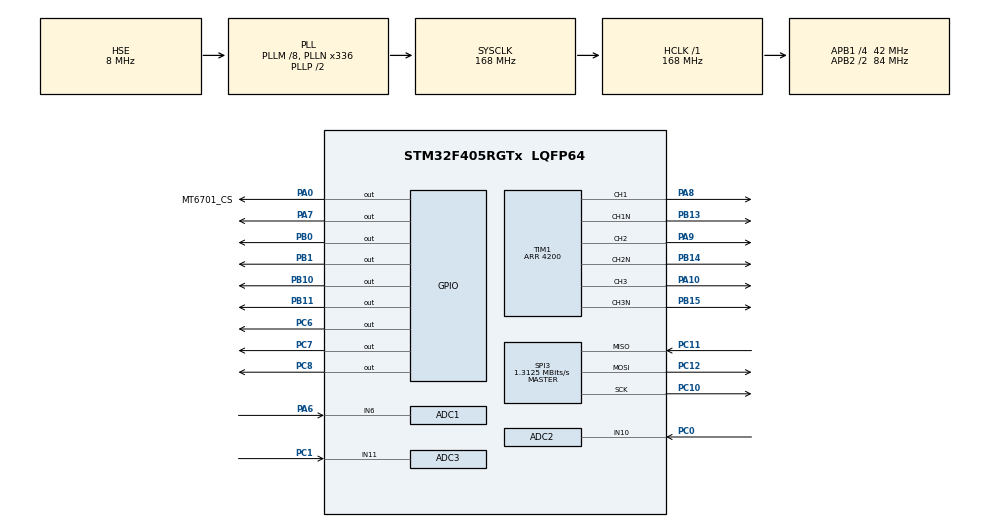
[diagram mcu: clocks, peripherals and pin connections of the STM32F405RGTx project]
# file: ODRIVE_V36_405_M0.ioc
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ADC1.Channel-0\#ChannelRegularConversion=ADC_CHANNEL_6
ADC1.Channel-1\#ChannelRegularConversion=ADC_CHANNEL_VREFINT
ADC1.ClockPrescaler=ADC_CLOCK_SYNC_PCLK_DIV4
ADC1.EOCSelection=ADC_EOC_SEQ_CONV
ADC1.NbrOfConversion=2
ADC1.NbrOfConversionFlag=1
ADC1.Rank-0\#ChannelRegularConversion=1
ADC1.Rank-1\#ChannelRegularConversion=2
ADC1.SamplingTime-0\#ChannelRegularConversion=ADC_SAMPLETIME_480CYCLES
ADC1.SamplingTime-1\#ChannelRegularConversion=ADC_SAMPLETIME_480CYCLES
ADC1.ScanConvMode=ENABLE
ADC1.master=1
ADC2.Channel-0\#ChannelInjectedConversion=ADC_CHANNEL_10
ADC2.Channel-0\#ChannelRegularConversion=ADC_CHANNEL_10
ADC2.ClockPrescaler=ADC_CLOCK_SYNC_PCLK_DIV4
ADC2.ExternalTrigInjecConv=ADC_EXTERNALTRIGINJECCONV_T1_TRGO
ADC2.ExternalTrigInjecConvEdge=ADC_EXTERNALTRIGINJECCONVEDGE_RISING
ADC2.InjNumberOfConversion=1
ADC2.InjectedConvMode=None
ADC2.InjectedRank-0\#ChannelInjectedConversion=1
ADC2.NbrOfConversionFlag=1
ADC2.Rank-0\#ChannelRegularConversion=1
ADC2.SamplingTime-0\#ChannelInjectedConversion=ADC_SAMPLETIME_15CYCLES
ADC2.SamplingTime-0\#ChannelRegularConversion=ADC_SAMPLETIME_3CYCLES
ADC3.Channel-0\#ChannelInjectedConversion=ADC_CHANNEL_11
ADC3.Channel-0\#ChannelRegularConversion=ADC_CHANNEL_11
ADC3.ClockPrescaler=ADC_CLOCK_SYNC_PCLK_DIV4
ADC3.ExternalTrigInjecConv=ADC_EXTERNALTRIGINJECCONV_T1_TRGO
ADC3.ExternalTrigInjecConvEdge=ADC_EXTERNALTRIGINJECCONVEDGE_RISING
ADC3.InjNumberOfConversion=1
ADC3.InjectedConvMode=None
ADC3.InjectedRank-0\#ChannelInjectedConversion=1
ADC3.NbrOfConversionFlag=1
ADC3.Rank-0\#ChannelRegularConversion=1
ADC3.SamplingTime-0\#ChannelInjectedConversion=ADC_SAMPLETIME_15CYCLES
ADC3.SamplingTime-0\#ChannelRegularConversion=ADC_SAMPLETIME_3CYCLES
Dma.ADC1.0.Direction=DMA_PERIPH_TO_MEMORY
Dma.ADC1.0.FIFOMode=DMA_FIFOMODE_DISABLE
Dma.ADC1.0.Instance=DMA2_Stream0
Dma.ADC1.0.MemDataAlignment=DMA_MDATAALIGN_HALFWORD
Dma.ADC1.0.MemInc=DMA_MINC_ENABLE
Dma.ADC1.0.Mode=DMA_NORMAL
Dma.ADC1.0.PeriphDataAlignment=DMA_PDATAALIGN_HALFWORD
Dma.ADC1.0.PeriphInc=DMA_PINC_DISABLE
Dma.ADC1.0.Priority=DMA_PRIORITY_HIGH
Dma.Request0=ADC1
Mcu.Family=STM32F4
Mcu.Name=STM32F405RGTx
Mcu.Package=LQFP64
NVIC.ADC_IRQn=true\:2\:0\:false\:false\:true\:true\:true\:true
NVIC.DMA2_Stream0_IRQn=true\:4\:0\:false\:false\:true\:true\:true\:true
NVIC.PriorityGroup=NVIC_PRIORITYGROUP_4
NVIC.SPI3_IRQn=true\:3\:0\:false\:false\:true\:true\:true\:true
NVIC.TIM1_UP_TIM10_IRQn=true\:1\:0\:false\:false\:true\:true\:true\:true
NVIC.TIM2_IRQn=true\:5\:0\:false\:false\:true\:true\:true\:true
PA0-WKUP.GPIO_Label=MT6701_CS
PA0-WKUP.PinState=GPIO_PIN_SET
PA0-WKUP.Signal=GPIO_Output
PA10.GPIO_PuPd=GPIO_PULLDOWN
PA10.Signal=S_TIM1_CH3
PA13.Mode=Serial_Wire
PA13.Signal=SYS_JTMS-SWDIO
PA14.Mode=Serial_Wire
PA14.Signal=SYS_JTCK-SWCLK
PA6.Signal=ADCx_IN6
PA7.Signal=GPIO_Output
PA8.GPIO_PuPd=GPIO_PULLDOWN
PA8.Signal=S_TIM1_CH1
PA9.GPIO_PuPd=GPIO_PULLDOWN
PA9.Signal=S_TIM1_CH2
PB0.Signal=GPIO_Output
PB1.Signal=GPIO_Output
PB10.Signal=GPIO_Output
PB11.Signal=GPIO_Output
PB13.GPIO_PuPd=GPIO_PULLDOWN
PB13.Mode=PWM Generation1 CH1 CH1N
PB13.Signal=TIM1_CH1N
PB14.GPIO_PuPd=GPIO_PULLDOWN
PB14.Mode=PWM Generation2 CH2 CH2N
PB14.Signal=TIM1_CH2N
PB15.GPIO_PuPd=GPIO_PULLDOWN
PB15.Mode=PWM Generation3 CH3 CH3N
PB15.Signal=TIM1_CH3N
PC0.Signal=ADCx_IN10
PC1.Signal=ADCx_IN11
PC10.Mode=Full_Duplex_Master
PC10.Signal=SPI3_SCK
PC11.Mode=Full_Duplex_Master
PC11.Signal=SPI3_MISO
PC12.Mode=Full_Duplex_Master
PC12.Signal=SPI3_MOSI
PC6.Signal=GPIO_Output
PC7.Signal=GPIO_Output
PC8.Signal=GPIO_Output
PH0-OSC_IN.Mode=HSE-External-Oscillator
PH0-OSC_IN.Signal=RCC_OSC_IN
PH1-OSC_OUT.Mode=HSE-External-Oscillator
PH1-OSC_OUT.Signal=RCC_OSC_OUT
ProjectManager.HeapSize=0x200
ProjectManager.StackSize=0x1000
ProjectManager.TargetToolchain=MDK-ARM V5
RCC.48MHZClocksFreq_Value=48000000
RCC.AHBFreq_Value=168000000
RCC.APB1CLKDivider=RCC_HCLK_DIV4
RCC.APB1Freq_Value=42000000
RCC.APB1TimFreq_Value=84000000
RCC.APB2CLKDivider=RCC_HCLK_DIV2
RCC.APB2Freq_Value=84000000
RCC.APB2TimFreq_Value=168000000
RCC.CortexFreq_Value=168000000
RCC.HCLKFreq_Value=168000000
RCC.HSE_VALUE=8000000
RCC.HSI_VALUE=16000000
RCC.LSE_VALUE=32768
RCC.PLLM=8
RCC.PLLN=336
RCC.PLLQ=7
RCC.PLLSourceVirtual=RCC_PLLSOURCE_HSE
RCC.RCC_RTC_Clock_Source_FROM_HSE=RCC_RTCCLKSOURCE_HSE_DIV8
RCC.SYSCLKFreq_VALUE=168000000
RCC.SYSCLKSource=RCC_SYSCLKSOURCE_PLLCLK
RCC.VCOOutputFreq_Value=336000000
SH.ADCx_IN10.0=ADC2_IN10,IN10
SH.ADCx_IN11.0=ADC3_IN11,IN11
SH.ADCx_IN6.0=ADC1_IN6,IN6
SH.S_TIM1_CH1.0=TIM1_CH1,PWM Generation1 CH1 CH1N
SH.S_TIM1_CH2.0=TIM1_CH2,PWM Generation2 CH2 CH2N
SH.S_TIM1_CH3.0=TIM1_CH3,PWM Generation3 CH3 CH3N
SPI3.BaudRatePrescaler=SPI_BAUDRATEPRESCALER_32
SPI3.CLKPolarity=SPI_POLARITY_HIGH
SPI3.CalculateBaudRate=1.3125 MBits/s
SPI3.Direction=SPI_DIRECTION_2LINES
SPI3.Mode=SPI_MODE_MASTER
SPI3.VirtualType=VM_MASTER
TIM1.Channel-PWM\ Generation1\ CH1\ CH1N=TIM_CHANNEL_1
TIM1.Channel-PWM\ Generation2\ CH2\ CH2N=TIM_CHANNEL_2
TIM1.Channel-PWM\ Generation3\ CH3\ CH3N=TIM_CHANNEL_3
TIM1.Channel-PWM\ Generation4\ No\ Output=TIM_CHANNEL_4
TIM1.CounterMode=TIM_COUNTERMODE_CENTERALIGNED1
TIM1.DeadTime=84
TIM1.OCMode_PWM-PWM\ Generation4\ No\ Output=TIM_OCMODE_PWM2
TIM1.OffStateIDLEMode=TIM_OSSI_ENABLE
TIM1.OffStateRunMode=TIM_OSSR_ENABLE
TIM1.Period=4200
TIM1.Pulse-PWM\ Generation1\ CH1\ CH1N=2100
TIM1.Pulse-PWM\ Generation2\ CH2\ CH2N=2100
TIM1.Pulse-PWM\ Generation3\ CH3\ CH3N=2100
TIM1.Pulse-PWM\ Generation4\ No\ Output=4116
TIM1.TIM_MasterOutputTrigger=TIM_TRGO_OC4REF
TIM2.Period=4294967295
TIM2.Prescaler=83
VP_ADC1_Vref_Input.Mode=IN-Vrefint
VP_TIM1_VS_ClockSourceINT.Mode=Internal
VP_TIM1_VS_no_output4.Mode=PWM Generation4 No Output
VP_TIM2_VS_ClockSourceINT.Mode=Internal
board=custom

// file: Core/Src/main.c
/* USER CODE BEGIN Header */
/**
  ******************************************************************************
  * @file           : main.c
  * @brief          : Main program body
  ******************************************************************************
  * @attention
  *
  * Copyright (c) 2026 STMicroelectronics.
  * All rights reserved.
  *
  * This software is licensed under terms that can be found in the LICENSE file
  * in the root directory of this software component.
  * If no LICENSE file comes with this software, it is provided AS-IS.
  *
  ******************************************************************************
  */
/* USER CODE END Header */
#include "main.h"
#include "adc.h"
#include "dma.h"
#include "spi.h"
#include "tim.h"
#include "gpio.h"

/* USER CODE BEGIN Includes */
#include "target_validation.h"
/* USER CODE END Includes */

void SystemClock_Config(void);

int main(void)
{

  /* MCU Configuration--------------------------------------------------------*/

  /* Reset of all peripherals, Initializes the Flash interface and the Systick. */
  HAL_Init();

  /* Configure the system clock */
  SystemClock_Config();

  /* Initialize all configured peripherals */
  MX_GPIO_Init();
  MX_DMA_Init();
  MX_ADC1_Init();
  MX_ADC2_Init();
  MX_ADC3_Init();
  MX_SPI3_Init();
  MX_TIM1_Init();
  MX_TIM2_Init();
  /* USER CODE BEGIN 2 */
    if (!target_validation_start()) {
        Error_Handler();
    }
    /* 默认只有观测；台架动作通过独立 mailbox 显式提交。 */
/* USER CODE END 2 */

  /* Infinite loop */
  while (1)
  {

    /* USER CODE BEGIN 3 */
    __WFI();
  }
/* USER CODE END 3 */
}

void SystemClock_Config(void)
{
  RCC_OscInitTypeDef RCC_OscInitStruct = {0};
  RCC_ClkInitTypeDef RCC_ClkInitStruct = {0};

  /** Configure the main internal regulator output voltage
  */
  __HAL_RCC_PWR_CLK_ENABLE();
  __HAL_PWR_VOLTAGESCALING_CONFIG(PWR_REGULATOR_VOLTAGE_SCALE1);

  /** Initializes the RCC Oscillators according to the specified parameters
  * in the RCC_OscInitTypeDef structure.
  */
  RCC_OscInitStruct.OscillatorType = RCC_OSCILLATORTYPE_HSE;
  RCC_OscInitStruct.HSEState = RCC_HSE_ON;
  RCC_OscInitStruct.PLL.PLLState = RCC_PLL_ON;
  RCC_OscInitStruct.PLL.PLLSource = RCC_PLLSOURCE_HSE;
  RCC_OscInitStruct.PLL.PLLM = 8;
  RCC_OscInitStruct.PLL.PLLN = 336;
  RCC_OscInitStruct.PLL.PLLP = RCC_PLLP_DIV2;
  RCC_OscInitStruct.PLL.PLLQ = 7;
  if (HAL_RCC_OscConfig(&RCC_OscInitStruct) != HAL_OK)
  {
    Error_Handler();
  }

  /** Initializes the CPU, AHB and APB buses clocks
  */
  RCC_ClkInitStruct.ClockType = RCC_CLOCKTYPE_HCLK|RCC_CLOCKTYPE_SYSCLK
                              |RCC_CLOCKTYPE_PCLK1|RCC_CLOCKTYPE_PCLK2;
  RCC_ClkInitStruct.SYSCLKSource = RCC_SYSCLKSOURCE_PLLCLK;
  RCC_ClkInitStruct.AHBCLKDivider = RCC_SYSCLK_DIV1;
  RCC_ClkInitStruct.APB1CLKDivider = RCC_HCLK_DIV4;
  RCC_ClkInitStruct.APB2CLKDivider = RCC_HCLK_DIV2;

  if (HAL_RCC_ClockConfig(&RCC_ClkInitStruct, FLASH_LATENCY_5) != HAL_OK)
  {
    Error_Handler();
  }
}

void Error_Handler(void)
{
  /* USER CODE BEGIN Error_Handler_Debug */
    realtime_motor_io_safe_off();
    __disable_irq();
    while (1) {
    }
  /* USER CODE END Error_Handler_Debug */
}
